# ATtiny13A register map
Vendor: Atmel; File version: 1.0
CPU: other r0p0, little endian, no MPU, no FPU, 4 interrupt priority bits
Registers are 8-bit, read-write, reset 0x0 unless marked. A register's access mark holds for its fields unless they carry their own. Offsets are from the block's base; [hi:lo] are bit positions; {n}, {i} and the like mark numbered series.

## EEPROM
Base 0x0000003C
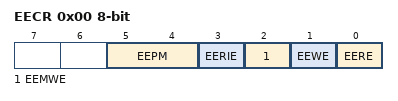
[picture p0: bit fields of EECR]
0x00 EECR — EEPROM Control Register
  [5:4] EEPM
    0=ERASE_AND_WRITE_IN_ONE_OPERATION; 1=ERASE_ONLY; 2=WRITE_ONLY
  [3] EERIE — EEProm Ready Interrupt Enable
  [2] EEMWE — EEPROM Master Write Enable
  [1] EEWE — EEPROM Write Enable
  [0] EERE — EEPROM Read Enable
0x01 EEDR — EEPROM Data Register
0x02 EEAR — EEPROM Read/Write Access

## EXINT — External Interrupts
Base 0x00000035
0x00 PCMSK — Pin Change Enable Mask
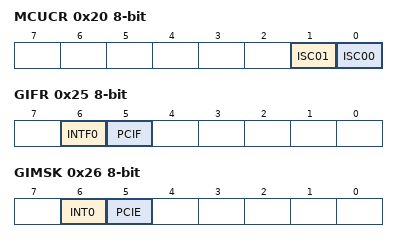
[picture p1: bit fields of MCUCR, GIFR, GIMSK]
0x20 MCUCR — MCU Control Register
  [1] ISC01 — Interrupt Sense Control 0 Bit 1
  [0] ISC00 — Interrupt Sense Control 0 Bit 0
    0=LOW_LEVEL_OF_INTX; 1=ANY_LOGICAL_CHANGE_OF_INTX
0x25 GIFR — General Interrupt Flag register
  [6] INTF0 — External Interrupt Flag 0
  [5] PCIF — Pin Change Interrupt Flag
0x26 GIMSK — General Interrupt Mask Register
  [6] INT0 — External Interrupt Request 0 Enable
  [5] PCIE — Pin Change Interrupt Enable

## FUSE — Fuses
Base 0x00000000
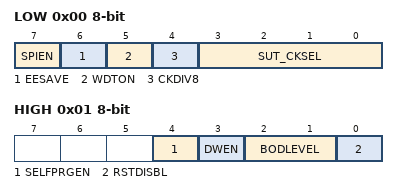
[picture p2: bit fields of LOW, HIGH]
0x00 LOW
  [7] SPIEN — Serial program downloading (SPI) enabled
  [6] EESAVE — Preserve EEPROM through the Chip Erase cycle
  [5] WDTON — Watch-dog Timer always on
  [4] CKDIV8 — Divide clock by 8 internally
  [3:0] SUT_CKSEL — Select Clock Source
    0=EXTCLK_14CK_0MS (Ext. Clock; Start-up time: 14 CK + 0 ms); 1=INTRCOSC_4MHZ8_14CK_0MS (Int. RC Osc. 4.8 MHz; Start-up time: 14 CK + 0 ms); 2=INTRCOSC_9MHZ6_14CK_0MS (Int. RC Osc. 9.6 MHz; Start-up time: 14 CK + 0 ms); 3=INTRCOSC_128KHZ_14CK_0MS (Int. RC Osc. 128 kHz; Start-up time: 14 CK + 0 ms); 4=EXTCLK_14CK_4MS (Ext. Clock; Start-up time: 14 CK + 4 ms); 5=INTRCOSC_4MHZ8_14CK_4MS (Int. RC Osc. 4.8 MHz; Start-up time: 14 CK + 4 ms); 6=INTRCOSC_9MHZ6_14CK_4MS (Int. RC Osc. 9.6 MHz; Start-up time: 14 CK + 4 ms); 7=INTRCOSC_128KHZ_14CK_4MS (Int. RC Osc. 128 kHz; Start-up time: 14 CK + 4 ms); 8=EXTCLK_14CK_64MS (Ext. Clock; Start-up time: 14 CK + 64 ms); 9=INTRCOSC_4MHZ8_14CK_64MS (Int. RC Osc. 4.8 MHz; Start-up time: 14 CK + 64 ms); 10=INTRCOSC_9MHZ6_14CK_64MS (Int. RC Osc. 9.6 MHz; Start-up time: 14 CK + 64 ms); 11=INTRCOSC_128KHZ_14CK_64MS (Int. RC Osc. 128 kHz; Start-up time: 14 CK + 64 ms)
0x01 HIGH
  [4] SELFPRGEN — Self Programming enable
  [3] DWEN — Debug Wire enable
  [2:1] BODLEVEL — Enable BOD and select level
    0=4V3 (Brown-out detection at VCC=4.3 V); 1=2V7 (Brown-out detection at VCC=2.7 V); 2=1V8 (Brown-out detection at VCC=1.8 V); 3=DISABLED (Brown-out detection disabled)
  [0] RSTDISBL — Reset Disabled (Enable PB5 as i/o pin)

## LOCKBIT — Lockbits
Base 0x00000000
0x00 LOCKBIT
  [1:0] LB — Memory Lock
    0=PROG_VER_DISABLED (Further programming and verification disabled); 2=PROG_DISABLED (Further programming disabled); 3=NO_LOCK (No memory lock features enabled)

## PORTB — I/O Port
Base 0x00000036
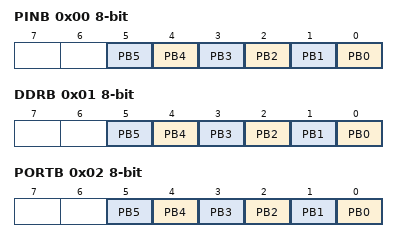
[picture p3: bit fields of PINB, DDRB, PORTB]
0x00 PINB — Input Pins, Port B
  [n] PB{n} (n=0..5) — Pin B{n}
0x01 DDRB — Data Direction Register, Port B
  [n] PB{n} (n=0..5) — Pin B{n}
0x02 PORTB — Data Register, Port B
  [n] PB{n} (n=0..5) — Pin B{n}

## TC0 — Timer/Counter, 8-bit
Base 0x00000048
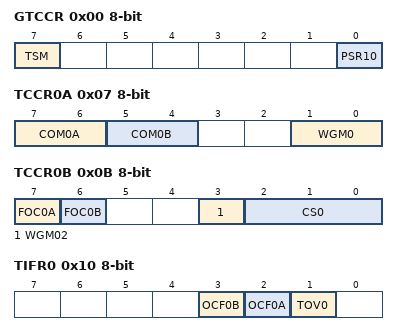
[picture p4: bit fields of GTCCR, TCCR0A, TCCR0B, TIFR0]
0x00 GTCCR — General Timer Conuter Register
  [7] TSM — Timer/Counter Synchronization Mode
  [0] PSR10 — Prescaler Reset Timer/Counter0
0x01 OCR0B — Timer/Counter0 Output Compare Register
0x07 TCCR0A — Timer/Counter Control Register A
  [7:6] COM0A — Compare Match Output A Mode
  [5:4] COM0B — Compare Match Output B Mode
  [1:0] WGM0 — Waveform Generation Mode
0x0A TCNT0 — Timer/Counter0
0x0B TCCR0B — Timer/Counter Control Register B
  [7] FOC0A — Force Output Compare A
  [6] FOC0B — Force Output Compare B
  [3] WGM02 — Waveform Generation Mode
  [2:0] CS0 — Clock Select
    0=NO_CLOCK_SOURCE_STOPPED; 1=RUNNING_NO_PRESCALING; 2=RUNNING_CLK_8; 3=RUNNING_CLK_64; 4=RUNNING_CLK_256; 5=RUNNING_CLK_1024; 6=RUNNING_EXTCLK_TN_FALLING_EDGE; 7=RUNNING_EXTCLK_TN_RISING_EDGE
0x0E OCR0A — Timer/Counter0 Output Compare Register
0x10 TIFR0 — Timer/Counter0 Interrupt Flag register
  [3] OCF0B — Timer/Counter0 Output Compare Flag 0B
  [2] OCF0A — Timer/Counter0 Output Compare Flag 0A
  [1] TOV0 — Timer/Counter0 Overflow Flag
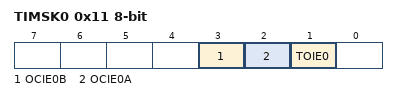
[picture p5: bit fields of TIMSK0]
0x11 TIMSK0 — Timer/Counter0 Interrupt Mask Register
  [3] OCIE0B — Timer/Counter0 Output Compare Match B Interrupt Enable
  [2] OCIE0A — Timer/Counter0 Output Compare Match A Interrupt Enable
  [1] TOIE0 — Timer/Counter0 Overflow Interrupt Enable

## WDT — Watchdog Timer
Base 0x00000041
0x00 WDTCR — Watchdog Timer Control Register
  [7] WDTIF — Watchdog Timeout Interrupt Flag
  [6] WDTIE — Watchdog Timeout Interrupt Enable
  [4] WDCE — Watchdog Change Enable
  [3] WDE — Watch Dog Enable
  [5:0] WDP — Watchdog Timer Prescaler Bits
    0=OSCILLATOR_CYCLES_2K; 1=OSCILLATOR_CYCLES_4K; 2=OSCILLATOR_CYCLES_8K; 3=OSCILLATOR_CYCLES_16K; 4=OSCILLATOR_CYCLES_32K; 5=OSCILLATOR_CYCLES_64K; 6=OSCILLATOR_CYCLES_128K; 7=OSCILLATOR_CYCLES_256K
